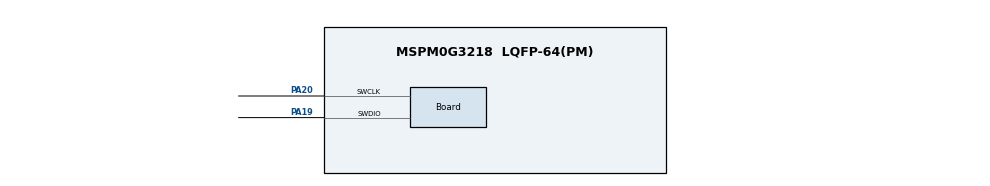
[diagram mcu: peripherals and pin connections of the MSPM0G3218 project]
//@cliArgs --device "MSPM0G321X" --package "LQFP-64(PM)" --part "Default"
//@v2CliArgs --device "MSPM0G3218" --package "LQFP-64(PM)"
// @cliArgs --board /ti/boards/LP_MSPM0G3218 --rtos nortos

/**
 * Import the modules used in this configuration.
 */
const Board         = scripting.addModule("/ti/driverlib/Board");
const ProjectConfig = scripting.addModule("/ti/project_config/ProjectConfig");
const SYSCTL = scripting.addModule("/ti/driverlib/SYSCTL");

/**
 * Write custom configuration values to the imported modules.
 */
Board.peripheral.$assign          = "DEBUGSS";
Board.peripheral.swclkPin.$assign = "PA20";
Board.peripheral.swdioPin.$assign = "PA19";

SYSCTL.forceDefaultClkConfig = true;
SYSCTL.clockTreeEn           = true;

ProjectConfig.migrationCondition = true;
